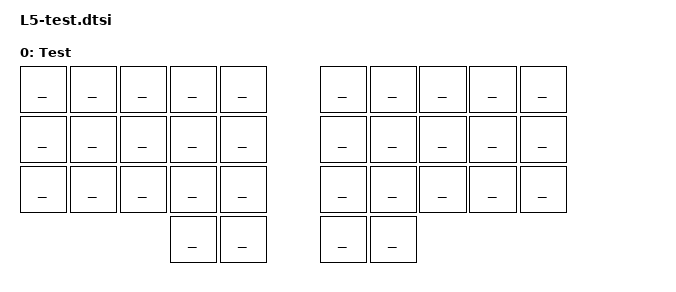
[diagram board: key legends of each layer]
/**
 *
 */

/ {
  keymap {
    compatible = "zmk,keymap";

	test_layer {
		label = "Test";
		bindings = <
//			╭───────────────┬───────────────┬───────────────┬───────────────┬───────────────╮   ╭───────────────┬───────────────┬───────────────┬───────────────┬───────────────╮
//  0               	1               2               3               4               5                   6               7               8               9               10
				________		________    	________		________		________			________        ________     	________        ________        ________
		//	├───────────────┼───────────────┼───────────────┼───────────────┼───────────────┤   ├───────────────├───────────────┼───────────────┼───────────────┼───────────────┤
//  12					13              14              15              16              17                  18              19              20              21              22
				________		________    	________		________		________			________        ________     	________        ________        ________
		//	├───────────────┼───────────────┼───────────────┼───────────────┼───────────────┤   ├───────────────├───────────────┼───────────────┼───────────────┼───────────────┤
//  24					25              26              27              28              29                  30              31              32              33              34
				________		________        ________        ________		________            ________        ________     	________        ________        ________
		//	╰───────────────┴───────────────┼───────────────┼───────────────┼───────────────┤   ├───────────────├───────────────┼───────────────┼───────────────┴───────────────╯
//	36              													37              38                  39              40
	       														________        ________           	________		________
//                                                          ╰───────────────┴───────────────╯   ╰───────────────┴───────────────╯

			>;
		};
	};
};
